# STM32L422 register map
File version: 1.0
CPU: CM4 r0p1, little endian, MPU, FPU, 4 interrupt priority bits
Registers are 32-bit, read-write, reset 0x0 unless marked. A register's access mark holds for its fields unless they carry their own. Offsets are from the block's base; [hi:lo] are bit positions.

## COMP — Comparator
Base 0x40010200
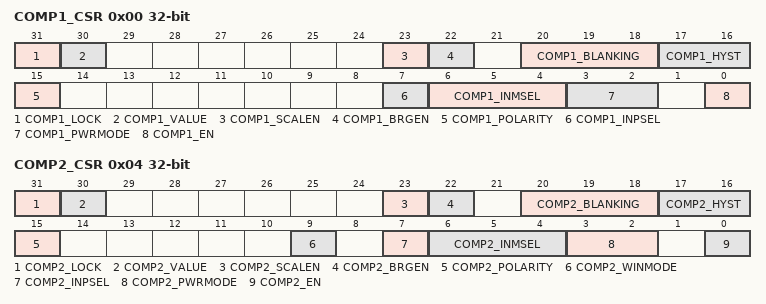
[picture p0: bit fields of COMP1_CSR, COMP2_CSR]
0x00 COMP1_CSR access per field — Comparator 1 control and status register
  [31] COMP1_LOCK wo — COMP1_CSR register lock bit
  [30] COMP1_VALUE ro — Comparator 1 output status bit
  [23] COMP1_SCALEN rw — Voltage scaler enable bit
  [22] COMP1_BRGEN rw — Scaler bridge enable
  [20:18] COMP1_BLANKING rw — Comparator 1 blanking source selection bits
  [17:16] COMP1_HYST rw — Comparator 1 hysteresis selection bits
  [15] COMP1_POLARITY rw — Comparator 1 polarity selection bit
  [7] COMP1_INPSEL rw — Comparator1 input plus selection bit
  [6:4] COMP1_INMSEL rw — Comparator 1 Input Minus connection configuration bit
  [3:2] COMP1_PWRMODE rw — Power Mode of the comparator 1
  [0] COMP1_EN rw — Comparator 1 enable bit
0x04 COMP2_CSR access per field — Comparator 2 control and status register
  [31] COMP2_LOCK wo — COMP2_CSR register lock bit
  [30] COMP2_VALUE ro — Comparator 2 output status bit
  [23] COMP2_SCALEN rw — Voltage scaler enable bit
  [22] COMP2_BRGEN rw — Scaler bridge enable
  [20:18] COMP2_BLANKING rw — Comparator 2 blanking source selection bits
  [17:16] COMP2_HYST rw — Comparator 2 hysteresis selection bits
  [15] COMP2_POLARITY rw — Comparator 2 polarity selection bit
  [9] COMP2_WINMODE rw — Windows mode selection bit
  [7] COMP2_INPSEL rw — Comparator 2 Input Plus connection configuration bit
  [6:4] COMP2_INMSEL rw — Comparator 2 Input Minus connection configuration bit
  [3:2] COMP2_PWRMODE rw — Power Mode of the comparator 2
  [0] COMP2_EN rw — Comparator 2 enable bit

## CRC — Cyclic redundancy check calculation unit
Base 0x40023000
0x00 DR reset 0xFFFFFFFF — Data register
  [31:0] DR — Data register bits
0x04 IDR — Independent data register
  [7:0] IDR — General-purpose 8-bit data register bits
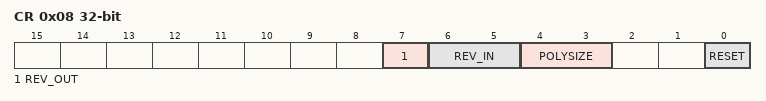
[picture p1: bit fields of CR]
0x08 CR access per field — Control register
  [7] REV_OUT rw — Reverse output data
  [6:5] REV_IN rw — Reverse input data
  [4:3] POLYSIZE rw — Polynomial size
  [0] RESET wo — RESET bit
0x10 INIT reset 0xFFFFFFFF — Initial CRC value
  [31:0] CRC_INIT — Programmable initial CRC value
0x14 POL reset 0x4C11DB7 — polynomial
  [31:0] Polynomialcoefficients — Programmable polynomial

## CRS — Clock recovery system
Base 0x40006000
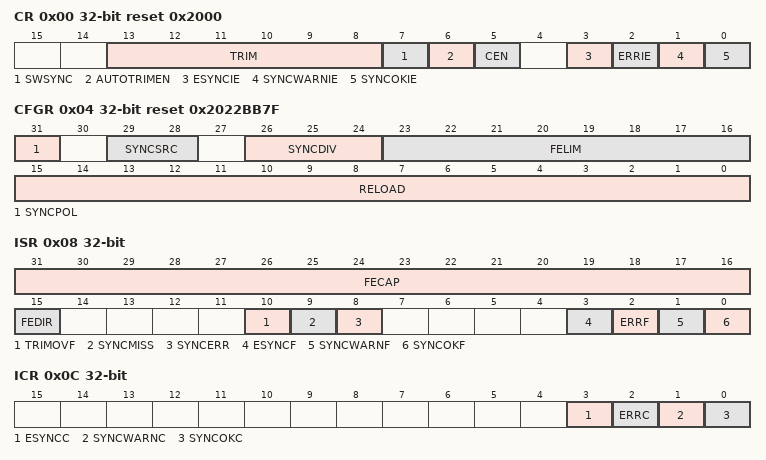
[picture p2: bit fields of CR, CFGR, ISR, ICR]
0x00 CR reset 0x2000 — control register
  [13:8] TRIM — HSI48 oscillator smooth trimming
  [7] SWSYNC — Generate software SYNC event
  [6] AUTOTRIMEN — Automatic trimming enable
  [5] CEN — Frequency error counter enable
  [3] ESYNCIE — Expected SYNC interrupt enable
  [2] ERRIE — Synchronization or trimming error interrupt enable
  [1] SYNCWARNIE — SYNC warning interrupt enable
  [0] SYNCOKIE — SYNC event OK interrupt enable
0x04 CFGR reset 0x2022BB7F — configuration register
  [31] SYNCPOL — SYNC polarity selection
  [29:28] SYNCSRC — SYNC signal source selection
  [26:24] SYNCDIV — SYNC divider
  [23:16] FELIM — Frequency error limit
  [15:0] RELOAD — Counter reload value
0x08 ISR ro — interrupt and status register
  [31:16] FECAP — Frequency error capture
  [15] FEDIR — Frequency error direction
  [10] TRIMOVF — Trimming overflow or underflow
  [9] SYNCMISS — SYNC missed
  [8] SYNCERR — SYNC error
  [3] ESYNCF — Expected SYNC flag
  [2] ERRF — Error flag
  [1] SYNCWARNF — SYNC warning flag
  [0] SYNCOKF — SYNC event OK flag
0x0C ICR — interrupt flag clear register
  [3] ESYNCC — Expected SYNC clear flag
  [2] ERRC — Error clear flag
  [1] SYNCWARNC — SYNC warning clear flag
  [0] SYNCOKC — SYNC event OK clear flag

## DBGMCU — MCU debug component
Base 0xE0042000
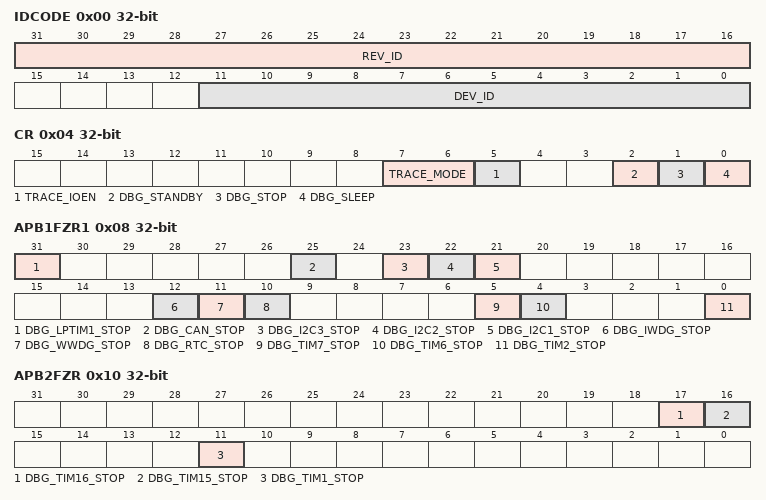
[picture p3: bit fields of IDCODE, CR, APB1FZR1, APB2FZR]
0x00 IDCODE ro — DBGMCU_IDCODE
  [31:16] REV_ID — Revision identifie
  [11:0] DEV_ID — Device identifier
0x04 CR — Debug MCU configuration register
  [7:6] TRACE_MODE — Trace pin assignment control
  [5] TRACE_IOEN — Trace pin assignment control
  [2] DBG_STANDBY — Debug Standby mode
  [1] DBG_STOP — Debug Stop mode
  [0] DBG_SLEEP — Debug Sleep mode
0x08 APB1FZR1 — Debug MCU APB1 freeze register1
  [31] DBG_LPTIM1_STOP — LPTIM1 counter stopped when core is halted
  [25] DBG_CAN_STOP — bxCAN stopped when core is halted
  [23] DBG_I2C3_STOP — I2C3 SMBUS timeout counter stopped when core is halted
  [22] DBG_I2C2_STOP — I2C2 SMBUS timeout counter stopped when core is halted
  [21] DBG_I2C1_STOP — I2C1 SMBUS timeout counter stopped when core is halted
  [12] DBG_IWDG_STOP — Independent watchdog counter stopped when core is halted
  [11] DBG_WWDG_STOP — Window watchdog counter stopped when core is halted
  [10] DBG_RTC_STOP — RTC counter stopped when core is halted
  [5] DBG_TIM7_STOP — TIM7 counter stopped when core is halted
  [4] DBG_TIM6_STOP — TIM6 counter stopped when core is halted
  [0] DBG_TIM2_STOP — TIM2 counter stopped when core is halted
0x0C APB1FZR2 — Debug MCU APB1 freeze register 2
  [5] DBG_LPTIM2_STOP — LPTIM2 counter stopped when core is halted
0x10 APB2FZR — Debug MCU APB2 freeze register
  [17] DBG_TIM16_STOP — TIM16 counter stopped when core is halted
  [16] DBG_TIM15_STOP — TIM15 counter stopped when core is halted
  [11] DBG_TIM1_STOP — TIM1 counter stopped when core is halted

## Notices in the file
Copyright (c) 2024 STMicroelectronics.
SPDX-License-Identifier: Apache-2.0
Licensed under the Apache License, Version 2.0 (the "License");
you may not use this file except in compliance with the License.
You may obtain a copy of the License at
http://www.apache.org/licenses/LICENSE-2.0
Unless required by applicable law or agreed to in writing, software
distributed under the License is distributed on an "AS IS" BASIS,
WITHOUT WARRANTIES OR CONDITIONS OF ANY KIND, either express or implied.
See the License for the specific language governing permissions and
limitations under the License.
